# RS14100 register map
File version: 1.0
CPU: CM4 r0p1, little endian, MPU, FPU, 4 interrupt priority bits
Registers are 32-bit, read-write, reset 0x0 unless marked. A register's access mark holds for its fields unless they carry their own. Offsets are from the block's base; [hi:lo] are bit positions; lines under a group give offsets from that group; {n}, {i} and the like mark numbered series.

## HWRNG — Random numbers generated are 16-bit random numbers and are generated using either the True random number generator or the Pseudo random number generator.
Base 0x45090000
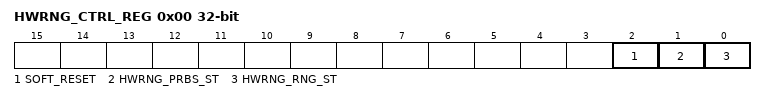
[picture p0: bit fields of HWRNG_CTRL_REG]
0x00 HWRNG_CTRL_REG — Random Number Generator Control Register
  [2] SOFT_RESET — This bit is used to start the pseudo random number generation
    1=Enable (Reset the scrambled data); 0=Disable (Not resetted)
  [1] HWRNG_PRBS_ST — This bit is used to start the pseudo random number generation
    1=Enables pseudo random number generation; 0=Disables pseudo random number generation
  [0] HWRNG_RNG_ST — This bit is used to start the true number generation.
    1=Enables true random number generation; 0=Disables true random number generation
0x04 HWRNG_RAND_NUM_REG ro — Hardware Random Number Register
  [31:0] HWRNG_RAND_NUM — Generated random number can be read from this register.

## TIMERS — TIMER can be used to generate various timing events for the software
Base 0x24042000
{0x0+4i} MATCH_CTRL[{i}] (i=0..3) group
  0x00 TMR_MATCH reset 0xFFFF (reset mask 0xFFFF) — Timer Match Register
    [31:0] TMR_MATCH — This bits are used to program the lower significant 16-bits of timer time out value in millisecond or number of system clocks
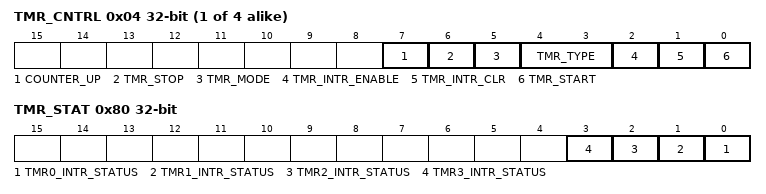
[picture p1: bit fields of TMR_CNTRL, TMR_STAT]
  0x04 TMR_CNTRL — Timer Control Register
    [7] COUNTER_UP — For reading/tracking counter in up counting this bit has to be set
    [6] TMR_STOP wo — This Bit are Used to stop the timer
      1=None (Stops the timer)
    [5] TMR_MODE — This Bit are Used to select the mode working of timer
      1=Enable (Periodic timer); 0=Disable (One shot timer)
    [4:3] TMR_TYPE — This Bit are Used to select the type of timer
      2=256_MICRO_SECOND (256 Micro second mode); 1=1_MICRO_SECOND (1 Micro second mode); 0=COUNT_DOWN_TIMER
    [2] TMR_INTR_ENABLE — This Bit are Used to enable the time out interrupt
      1=enable (Interrupt enable); 0=disable (Interrupt disable)
    [1] TMR_INTR_CLR wo — This Bit are Used to clear the timer
      1=None (Clear interrupt)
    [0] TMR_START wo — This Bit are Used to start the timer timer gets reset upon setting this bit
      1=None (Timer start)
0x80 TMR_STAT — Timer Status Register
  [all] fields
    1=INTERRUPT_PRESENT; 0=INTERRUPT_ABSENT (No Interrupt present)
  [n] TMR{n}_INTR_STATUS (n=0..3) — This bit indicates status of the interrupt generated by timer {n}
0x84 TMR_US_PERIOD_INT reset 0xFFFF — Timer micro second period Integral Part Register
  [15:0] TMR_US_PERIOD_INT — This bits are used to program the integer part of number of clock cycles per microseconds of the system clock used
0x88 TMR_US_PERIOD_FRAC reset 0xFF — Timer microsecond period Fractional Part Register
  [7:0] TMR_US_PERIOD_FRAC — This bits are used to program the fractional part of number of clock cycles per microseconds of the system clock used
0x8C TMR_MS_PERIOD_INT reset 0xFFFF — Timer 256 microsecond period Integral Part Register
  [15:0] TMR_MS_PERIOD_INT — This bits are used to program the integer part of number of clock cycles per 256 microseconds of the system clock used
0x90 TMR_MS_PERIOD_FRAC reset 0xFF — Timer 256 microsecond period Fractional Part Register
  [7:0] TMR_MS_PERIOD_FRAC_ — This bits are used to program the fractional part of number of clock cycles per 256 microseconds of the system clock used

## IID_AES — The AES module provides AES encoding and decoding functionality. It can be used in a microprocessor based environment
Base 0x20480500
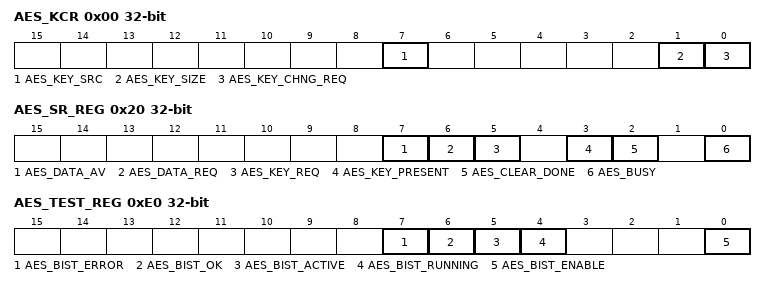
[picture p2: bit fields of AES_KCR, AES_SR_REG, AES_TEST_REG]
0x00 AES_KCR — AES Key Control register
  [7] AES_KEY_SRC — Source of the AES key 0: Interface 1: Register
  [1] AES_KEY_SIZE — Size of the AES key 0: 128-bit 1: 256-bit
  [0] AES_KEY_CHNG_REQ — Programming 1 clears the current key and starts a request a for a new key Auto-reverts to 0 as soon as the request is accepted
0x04 AES_MODE_REG — AES Mode register
  [7:0] AES_MODE — The AES Mode register defines which mode of AES is used.
0x08 AES_ACT_REG — AES Action register
  [1:0] AES_ACTION — The AES Mode register defines which mode of AES is used.
    0=Idle; 1=Encode; 2=Decode; 3=Clear
0x20 AES_SR_REG ro — AES Status register
  [7] AES_DATA_AV — Indicates that data is available
    1=Enable (Indicates that data is available); 0=Disable (none)
  [6] AES_DATA_REQ — Indicates that data must be provided
    1=Enable (Indicates that data must be provided); 0=Disable (none)
  [5] AES_KEY_REQ — Indicates that a key must be provided
    1=Enable (Indicates that a key must be provided); 0=Disable (none)
  [3] AES_KEY_PRESENT — Indicates that the Clear action is finished
    1=Enable (Indicates that a complete key is present); 0=Disable (none)
  [2] AES_CLEAR_DONE — Indicates that the Clear action is finished
    1=Enable (Indicates that the Clear action is finished); 0=Disable (none)
  [0] AES_BUSY — Indicates that the AES core is processing data
    1=Enable (Indicates that the AES core is processing data); 0=Disable (none)
0x40 AES_KEY_REG wo — The AES Key register is used to program a key into the AES module.
  [31:0] AES_KEY — 4 writes of 32 bits make up the 128-bit key for AES, 8 writes make up the 256-bit key
0x44 AES_DIN_REG wo — AES Data In register
  [31:0] AES_DIN — Data for encoding or decoding, 4 writes of 32 bits make up a 128-bit data word
0x48 AES_DOUT_REG ro — AES Data out register
  [31:0] AES_DOUT — Result from encoding or decoding, 4 reads of 32 bits make up a 128-bit data word
0xDC AES_IF_SR_REG ro — AES Interface Status register
  [0] IF_ERROR — Indicates that an interface error has occurred
0xDC AES_IF_SR_C_REG wo (alternate view of AES_IF_SR_REG) — AES Interface Status Clear register
  [0] IFB_ERROR — Clears the if_error bit
0xE0 AES_TEST_REG — AES Test register
  [7] AES_BIST_ERROR — Indicates that the BIST has failed
  [6] AES_BIST_OK — Indicates that the BIST has passed
  [5] AES_BIST_ACTIVE — Indicates that the BIST is running
  [4] AES_BIST_RUNNING — BIST is in progress or finishing up
  [0] AES_BIST_ENABLE — Isolates the iid_aes module and runs a BIST
0xFC AES_VER_REG ro — AES Version register
  [31:0] AES_VERSION — Version of iid_aes
